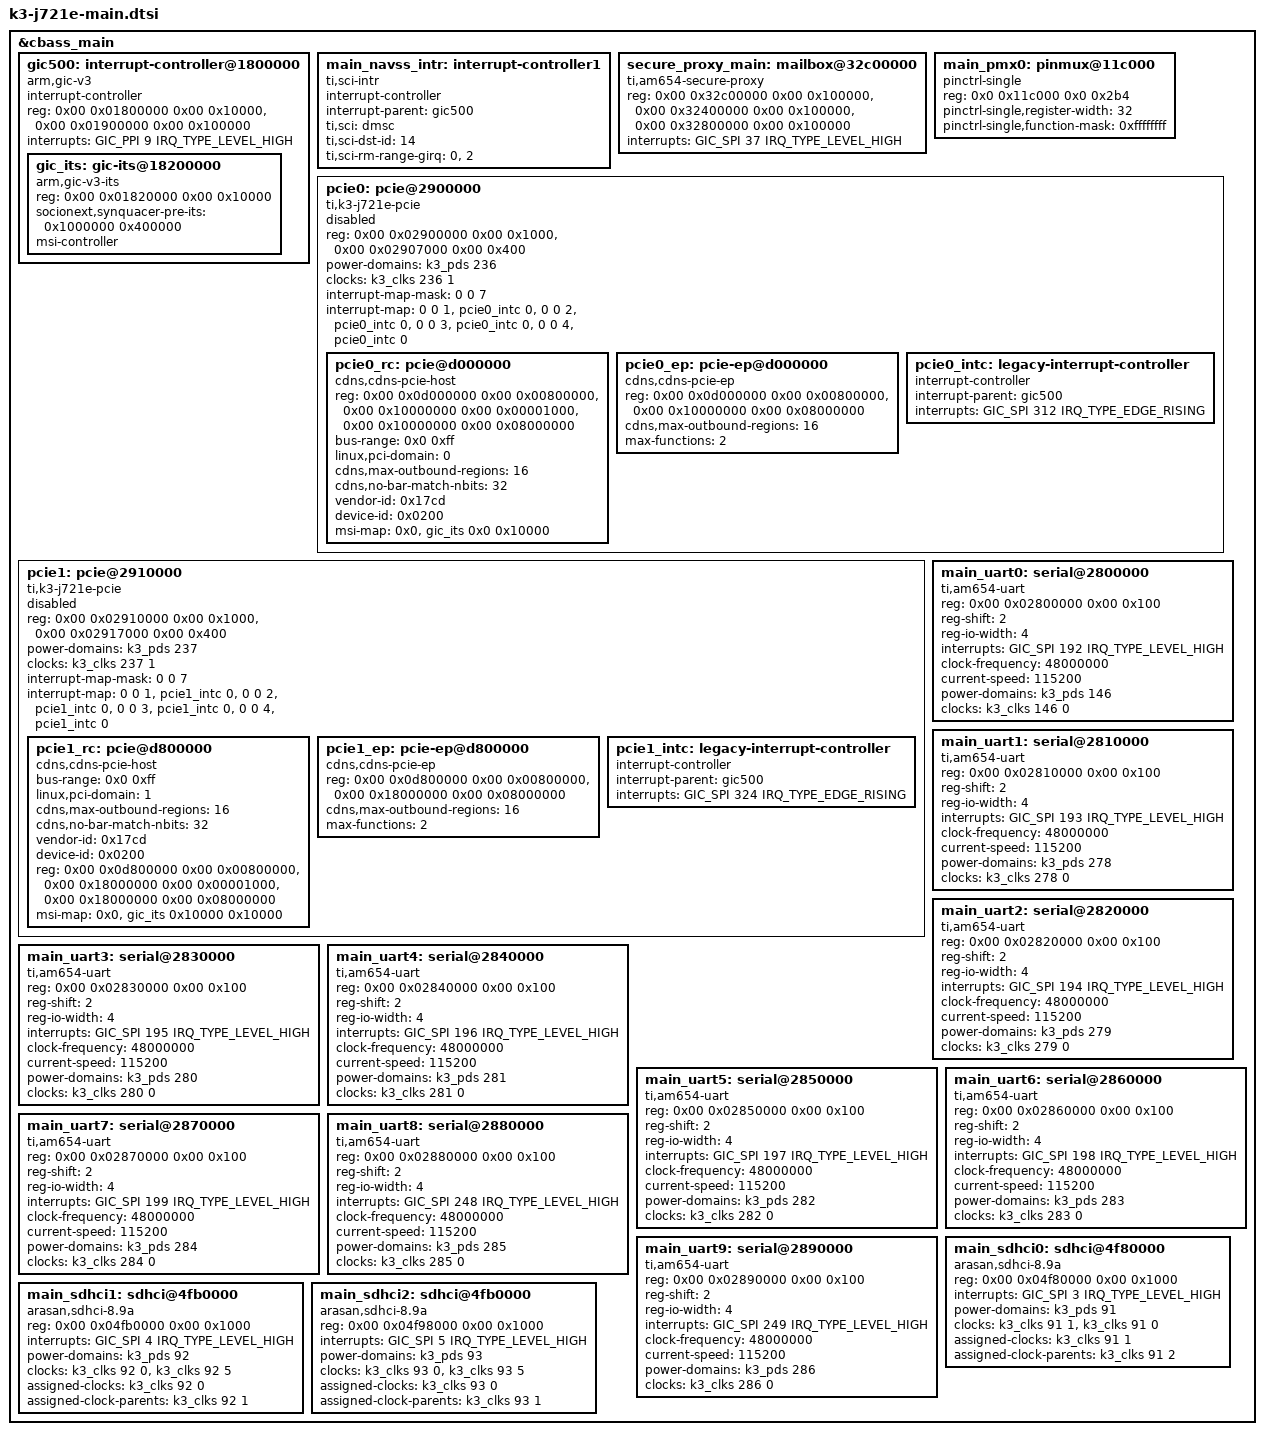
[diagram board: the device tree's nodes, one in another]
// SPDX-License-Identifier: GPL-2.0
/*
 * Device Tree Source for J721E SoC Family Main Domain peripherals
 *
 * Copyright (C) 2016-2019 Texas Instruments Incorporated - http://www.ti.com/
 */

&cbass_main {
	gic500: interrupt-controller@1800000 {
		compatible = "arm,gic-v3";
		#address-cells = <2>;
		#size-cells = <2>;
		ranges;
		#interrupt-cells = <3>;
		interrupt-controller;
		reg = <0x00 0x01800000 0x00 0x10000>,	/* GICD */
		      <0x00 0x01900000 0x00 0x100000>;	/* GICR */

		/* vcpumntirq: virtual CPU interface maintenance interrupt */
		interrupts = <GIC_PPI 9 IRQ_TYPE_LEVEL_HIGH>;

		gic_its: gic-its@18200000 {
			compatible = "arm,gic-v3-its";
			reg = <0x00 0x01820000 0x00 0x10000>;
			socionext,synquacer-pre-its = <0x1000000 0x400000>;
			msi-controller;
			#msi-cells = <1>;
		};
	};

	main_navss_intr: interrupt-controller1 {
		compatible = "ti,sci-intr";
		interrupt-controller;
		interrupt-parent = <&gic500>;
		#interrupt-cells = <3>;
		ti,sci = <&dmsc>;
		ti,sci-dst-id = <14>;
		ti,sci-rm-range-girq = <0>, <2>;
	};

	secure_proxy_main: mailbox@32c00000 {
		compatible = "ti,am654-secure-proxy";
		#mbox-cells = <1>;
		reg-names = "target_data", "rt", "scfg";
		reg = <0x00 0x32c00000 0x00 0x100000>,
		      <0x00 0x32400000 0x00 0x100000>,
		      <0x00 0x32800000 0x00 0x100000>;
		interrupt-names = "rx_011";
		interrupts = <GIC_SPI 37 IRQ_TYPE_LEVEL_HIGH>;
	};

	main_pmx0: pinmux@11c000 {
		compatible = "pinctrl-single";
		/* Proxy 0 addressing */
		reg = <0x0 0x11c000 0x0 0x2b4>;
		#pinctrl-cells = <1>;
		pinctrl-single,register-width = <32>;
		pinctrl-single,function-mask = <0xffffffff>;
	};

	pcie0: pcie@2900000 {
		compatible = "ti,k3-j721e-pcie";
		reg = <0x00 0x02900000 0x00 0x1000>,
		      <0x00 0x02907000 0x00 0x400>;
		reg-names = "intd_cfg", "user_cfg";
		#address-cells = <2>;
		#size-cells = <2>;
		ranges;
		power-domains = <&k3_pds 236>;
		clocks = <&k3_clks 236 1>;
		clock-names = "fck";
		#interrupt-cells = <1>;
		interrupt-map-mask = <0 0 7>;
		interrupt-map = <0 0 1 &pcie0_intc 0>, /* INT A */
				<0 0 2 &pcie0_intc 0>, /* INT B */
				<0 0 3 &pcie0_intc 0>, /* INT C */
				<0 0 4 &pcie0_intc 0>; /* INT D */
		status = "disabled";

		pcie0_rc: pcie@d000000 {
			compatible = "cdns,cdns-pcie-host";
			reg = <0x00 0x0d000000 0x00 0x00800000>,
			      <0x00 0x10000000 0x00 0x00001000>,
			      <0x00 0x10000000 0x00 0x08000000>;
			reg-names = "reg", "cfg", "mem";
			device_type = "pci";
			#address-cells = <3>;
			#size-cells = <2>;
			bus-range = <0x0 0xff>;
			linux,pci-domain = <0>;
			cdns,max-outbound-regions = <16>;
			cdns,no-bar-match-nbits = <32>;
			vendor-id = /bits/ 16 <0x17cd>;
			device-id = /bits/ 16 <0x0200>;
			msi-map = <0x0 &gic_its 0x0 0x10000>;
			ranges = <0x01000000 0x0 0x10001000  0x00 0x10001000  0x0 0x0010000>,
				 <0x02000000 0x0 0x10011000  0x00 0x10011000  0x0 0x7fef000>;
		};

		pcie0_ep: pcie-ep@d000000 {
			compatible = "cdns,cdns-pcie-ep";
			reg = <0x00 0x0d000000 0x00 0x00800000>,
			      <0x00 0x10000000 0x00 0x08000000>;
			reg-names = "reg", "mem";
			cdns,max-outbound-regions = <16>;
			max-functions = /bits/ 8 <2>;
		};

		pcie0_intc: legacy-interrupt-controller {
			interrupt-controller;
			#interrupt-cells = <1>;
			interrupt-parent = <&gic500>;
			interrupts = <GIC_SPI 312 IRQ_TYPE_EDGE_RISING>;
		};
	};

	pcie1: pcie@2910000 {
		compatible = "ti,k3-j721e-pcie";
		reg = <0x00 0x02910000 0x00 0x1000>,
		      <0x00 0x02917000 0x00 0x400>;
		reg-names = "intd_cfg", "user_cfg";
		#address-cells = <2>;
		#size-cells = <2>;
		ranges;
		power-domains = <&k3_pds 237>;
		clocks = <&k3_clks 237 1>;
		clock-names = "fck";
		#interrupt-cells = <1>;
		interrupt-map-mask = <0 0 7>;
		interrupt-map = <0 0 1 &pcie1_intc 0>, /* INT A */
				<0 0 2 &pcie1_intc 0>, /* INT B */
				<0 0 3 &pcie1_intc 0>, /* INT C */
				<0 0 4 &pcie1_intc 0>; /* INT D */
		status = "disabled";

		pcie1_rc: pcie@d800000 {
			compatible = "cdns,cdns-pcie-host";
			device_type = "pci";
			#address-cells = <3>;
			#size-cells = <2>;
			bus-range = <0x0 0xff>;
			linux,pci-domain = <1>;
			cdns,max-outbound-regions = <16>;
			cdns,no-bar-match-nbits = <32>;
			vendor-id = /bits/ 16 <0x17cd>;
			device-id = /bits/ 16 <0x0200>;
			reg = <0x00 0x0d800000 0x00 0x00800000>,
			      <0x00 0x18000000 0x00 0x00001000>,
			      <0x00 0x18000000 0x00 0x08000000>;
			reg-names = "reg", "cfg", "mem";
			msi-map = <0x0 &gic_its 0x10000 0x10000>;
			ranges = <0x01000000 0x0 0x18001000  0x00 0x18001000  0x0 0x0010000>,
				 <0x02000000 0x0 0x18011000  0x00 0x18011000  0x0 0x7fef000>;
		};

		pcie1_ep: pcie-ep@d800000 {
			compatible = "cdns,cdns-pcie-ep";
			reg = <0x00 0x0d800000 0x00 0x00800000>,
			      <0x00 0x18000000 0x00 0x08000000>;
			reg-names = "reg", "mem";
			cdns,max-outbound-regions = <16>;
			max-functions = /bits/ 8 <2>;
		};

		pcie1_intc: legacy-interrupt-controller {
			interrupt-controller;
			#interrupt-cells = <1>;
			interrupt-parent = <&gic500>;
			interrupts = <GIC_SPI 324 IRQ_TYPE_EDGE_RISING>;
		};
	};

	main_uart0: serial@2800000 {
		compatible = "ti,am654-uart";
		reg = <0x00 0x02800000 0x00 0x100>;
		reg-shift = <2>;
		reg-io-width = <4>;
		interrupts = <GIC_SPI 192 IRQ_TYPE_LEVEL_HIGH>;
		clock-frequency = <48000000>;
		current-speed = <115200>;
		power-domains = <&k3_pds 146>;
		clocks = <&k3_clks 146 0>;
		clock-names = "fclk";
	};

	main_uart1: serial@2810000 {
		compatible = "ti,am654-uart";
		reg = <0x00 0x02810000 0x00 0x100>;
		reg-shift = <2>;
		reg-io-width = <4>;
		interrupts = <GIC_SPI 193 IRQ_TYPE_LEVEL_HIGH>;
		clock-frequency = <48000000>;
		current-speed = <115200>;
		power-domains = <&k3_pds 278>;
		clocks = <&k3_clks 278 0>;
		clock-names = "fclk";
	};

	main_uart2: serial@2820000 {
		compatible = "ti,am654-uart";
		reg = <0x00 0x02820000 0x00 0x100>;
		reg-shift = <2>;
		reg-io-width = <4>;
		interrupts = <GIC_SPI 194 IRQ_TYPE_LEVEL_HIGH>;
		clock-frequency = <48000000>;
		current-speed = <115200>;
		power-domains = <&k3_pds 279>;
		clocks = <&k3_clks 279 0>;
		clock-names = "fclk";
	};

	main_uart3: serial@2830000 {
		compatible = "ti,am654-uart";
		reg = <0x00 0x02830000 0x00 0x100>;
		reg-shift = <2>;
		reg-io-width = <4>;
		interrupts = <GIC_SPI 195 IRQ_TYPE_LEVEL_HIGH>;
		clock-frequency = <48000000>;
		current-speed = <115200>;
		power-domains = <&k3_pds 280>;
		clocks = <&k3_clks 280 0>;
		clock-names = "fclk";
	};

	main_uart4: serial@2840000 {
		compatible = "ti,am654-uart";
		reg = <0x00 0x02840000 0x00 0x100>;
		reg-shift = <2>;
		reg-io-width = <4>;
		interrupts = <GIC_SPI 196 IRQ_TYPE_LEVEL_HIGH>;
		clock-frequency = <48000000>;
		current-speed = <115200>;
		power-domains = <&k3_pds 281>;
		clocks = <&k3_clks 281 0>;
		clock-names = "fclk";
	};

	main_uart5: serial@2850000 {
		compatible = "ti,am654-uart";
		reg = <0x00 0x02850000 0x00 0x100>;
		reg-shift = <2>;
		reg-io-width = <4>;
		interrupts = <GIC_SPI 197 IRQ_TYPE_LEVEL_HIGH>;
		clock-frequency = <48000000>;
		current-speed = <115200>;
		power-domains = <&k3_pds 282>;
		clocks = <&k3_clks 282 0>;
		clock-names = "fclk";
	};

	main_uart6: serial@2860000 {
		compatible = "ti,am654-uart";
		reg = <0x00 0x02860000 0x00 0x100>;
		reg-shift = <2>;
		reg-io-width = <4>;
		interrupts = <GIC_SPI 198 IRQ_TYPE_LEVEL_HIGH>;
		clock-frequency = <48000000>;
		current-speed = <115200>;
		power-domains = <&k3_pds 283>;
		clocks = <&k3_clks 283 0>;
		clock-names = "fclk";
	};

	main_uart7: serial@2870000 {
		compatible = "ti,am654-uart";
		reg = <0x00 0x02870000 0x00 0x100>;
		reg-shift = <2>;
		reg-io-width = <4>;
		interrupts = <GIC_SPI 199 IRQ_TYPE_LEVEL_HIGH>;
		clock-frequency = <48000000>;
		current-speed = <115200>;
		power-domains = <&k3_pds 284>;
		clocks = <&k3_clks 284 0>;
		clock-names = "fclk";
	};

	main_uart8: serial@2880000 {
		compatible = "ti,am654-uart";
		reg = <0x00 0x02880000 0x00 0x100>;
		reg-shift = <2>;
		reg-io-width = <4>;
		interrupts = <GIC_SPI 248 IRQ_TYPE_LEVEL_HIGH>;
		clock-frequency = <48000000>;
		current-speed = <115200>;
		power-domains = <&k3_pds 285>;
		clocks = <&k3_clks 285 0>;
		clock-names = "fclk";
	};

	main_uart9: serial@2890000 {
		compatible = "ti,am654-uart";
		reg = <0x00 0x02890000 0x00 0x100>;
		reg-shift = <2>;
		reg-io-width = <4>;
		interrupts = <GIC_SPI 249 IRQ_TYPE_LEVEL_HIGH>;
		clock-frequency = <48000000>;
		current-speed = <115200>;
		power-domains = <&k3_pds 286>;
		clocks = <&k3_clks 286 0>;
		clock-names = "fclk";
	};

	main_sdhci0: sdhci@4f80000 {
		compatible = "arasan,sdhci-8.9a";
		reg = <0x00 0x04f80000 0x00 0x1000>;
		interrupts = <GIC_SPI 3 IRQ_TYPE_LEVEL_HIGH>;
		power-domains = <&k3_pds 91>;
		clock-names = "clk_xin", "clk_ahb";
		clocks = <&k3_clks 91 1>, <&k3_clks 91 0>;
		assigned-clocks = <&k3_clks 91 1>;
		assigned-clock-parents = <&k3_clks 91 2>;
	};

	main_sdhci1: sdhci@4fb0000 {
		compatible = "arasan,sdhci-8.9a";
		reg = <0x00 0x04fb0000 0x00 0x1000>;
		interrupts = <GIC_SPI 4 IRQ_TYPE_LEVEL_HIGH>;
		power-domains = <&k3_pds 92>;
		clock-names = "clk_xin", "clk_ahb";
		clocks = <&k3_clks 92 0>, <&k3_clks 92 5>;
		assigned-clocks = <&k3_clks 92 0>;
		assigned-clock-parents = <&k3_clks 92 1>;
	};

	main_sdhci2: sdhci@4fb0000 {
		compatible = "arasan,sdhci-8.9a";
		reg = <0x00 0x04f98000 0x00 0x1000>;
		interrupts = <GIC_SPI 5 IRQ_TYPE_LEVEL_HIGH>;
		power-domains = <&k3_pds 93>;
		clock-names = "clk_xin", "clk_ahb";
		clocks = <&k3_clks 93 0>, <&k3_clks 93 5>;
		assigned-clocks = <&k3_clks 93 0>;
		assigned-clock-parents = <&k3_clks 93 1>;
	};
};
